VERSION ""

NS_ :

BS_:

BU_: Motor_VA_info Motor_Controller BMS
VAL_TABLE_ Charger_control 1 "Stop Charging" 0 "Start Charging" ;
VAL_TABLE_ Battery_Failure_level 3 "Level 3 Alarm" 2 "Level 2 Power reduced to 50%" 1 "Level 1 stop" 0 "No failure" ;
VAL_TABLE_ ChargeMOS_Status 1 "ChargeMOS On" 0 "ChargeMOS Off" ;
VAL_TABLE_ DisMOS_Status 1 "DisMOS On" 0 "DisMOS off" ;
VAL_TABLE_ Ready_State 1 "Ready" 0 "Not Ready" ;
VAL_TABLE_ Battery_Low_SOC 1 "Low SOC" 0 "Normal SOC" ;
VAL_TABLE_ Battery_Charging 1 "Charging" 0 "Not charging" ;
VAL_TABLE_ Charge_wire_status 1 "Charge Wire connected" 0 "Charge Wire not connected" ;

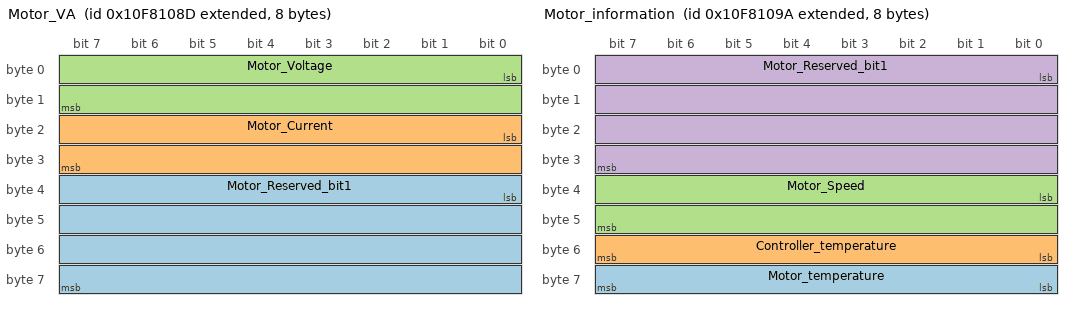
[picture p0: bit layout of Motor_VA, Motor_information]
BO_ 2432176269 Motor_VA: 8 Motor_VA_info
 SG_ Motor_Reserved_bit1 : 32|32@1- (1,0) [0|0] ""  Motor_VA_info
 SG_ Motor_Current : 16|16@1- (0.1,0) [0|0] ""  Motor_VA_info
 SG_ Motor_Voltage : 0|16@1+ (0.1,0) [0|6553.5] "V"  Motor_VA_info

BO_ 2432176282 Motor_information: 8 Motor_Controller
 SG_ Motor_temperature : 56|8@1+ (1,-40) [-40|215] "degC"  Motor_Controller
 SG_ Controller_temperature : 48|8@1+ (1,-40) [-40|215] "degC"  Motor_Controller
 SG_ Motor_Speed : 32|16@1+ (1,0) [0|65535] "RPM"  Motor_Controller
 SG_ Motor_Reserved_bit1 : 0|32@1- (1,0) [0|0] ""  Motor_Controller

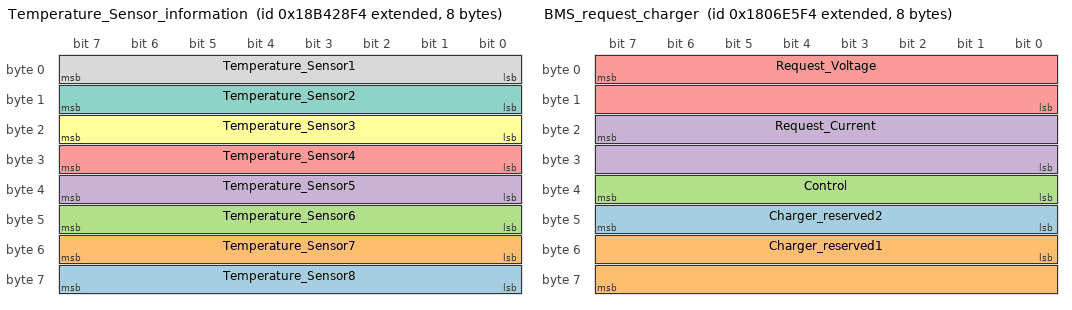
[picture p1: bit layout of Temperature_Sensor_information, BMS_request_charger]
BO_ 2561943796 Temperature_Sensor_information: 8 BMS
 SG_ Temperature_Sensor8 : 56|8@1+ (1,-40) [-40|215] "degC"  BMS
 SG_ Temperature_Sensor7 : 48|8@1+ (1,-40) [-40|215] "degC"  BMS
 SG_ Temperature_Sensor6 : 40|8@1+ (1,-40) [-40|215] "degC"  BMS
 SG_ Temperature_Sensor5 : 32|8@1+ (1,-40) [-40|215] "degC"  BMS
 SG_ Temperature_Sensor4 : 24|8@1+ (1,-40) [-40|215] "degC"  BMS
 SG_ Temperature_Sensor3 : 16|8@1+ (1,-40) [-40|215] "degC"  BMS
 SG_ Temperature_Sensor2 : 8|8@1+ (1,-40) [-40|215] "degC"  BMS
 SG_ Temperature_Sensor1 : 0|8@1+ (1,-40) [-40|215] "degC"  BMS

BO_ 2550588916 BMS_request_charger: 8 BMS
 SG_ Charger_reserved2 : 40|8@1- (1,0) [0|0] ""  BMS
 SG_ Charger_reserved1 : 48|16@1- (1,0) [0|0] ""  BMS
 SG_ Control : 32|8@1+ (1,0) [0|0] ""  BMS
 SG_ Request_Current : 23|16@0+ (0.1,0) [0|6553.5] "A"  BMS
 SG_ Request_Voltage : 7|16@0+ (0.1,0) [0|6553.5] "V"  BMS

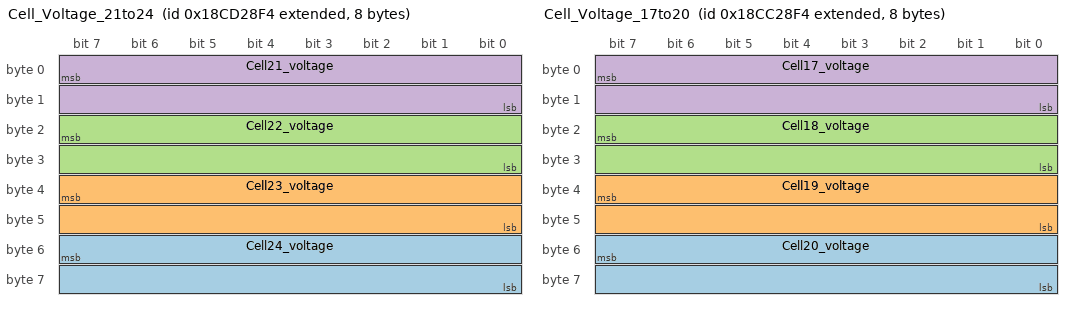
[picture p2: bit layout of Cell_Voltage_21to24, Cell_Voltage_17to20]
BO_ 2563582196 Cell_Voltage_21to24: 8 BMS
 SG_ Cell24_voltage : 55|16@0+ (0.001,0) [0|65.535] "V"  BMS
 SG_ Cell23_voltage : 39|16@0+ (0.001,0) [0|65.535] "V"  BMS
 SG_ Cell22_voltage : 23|16@0+ (0.001,0) [0|65.535] "V"  BMS
 SG_ Cell21_voltage : 7|16@0+ (0.001,0) [0|65.535] "V"  BMS

BO_ 2563516660 Cell_Voltage_17to20: 8 BMS
 SG_ Cell20_voltage : 55|16@0+ (0.001,0) [0|65.535] "V"  BMS
 SG_ Cell19_voltage : 39|16@0+ (0.001,0) [0|65.535] "V"  BMS
 SG_ Cell18_voltage : 23|16@0+ (0.001,0) [0|65.535] "V"  BMS
 SG_ Cell17_voltage : 7|16@0+ (0.001,0) [0|65.535] "V"  BMS

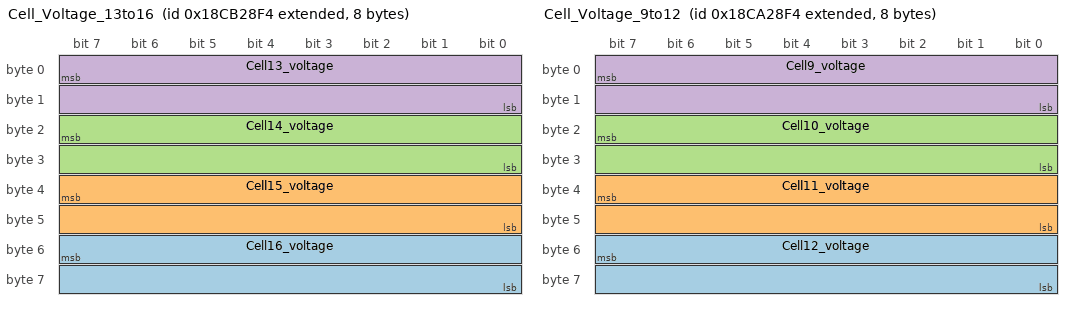
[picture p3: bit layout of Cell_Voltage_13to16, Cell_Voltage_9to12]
BO_ 2563451124 Cell_Voltage_13to16: 8 BMS
 SG_ Cell16_voltage : 55|16@0+ (0.001,0) [0|65.535] "V"  BMS
 SG_ Cell15_voltage : 39|16@0+ (0.001,0) [0|65.535] "V"  BMS
 SG_ Cell14_voltage : 23|16@0+ (0.001,0) [0|65.535] "V"  BMS
 SG_ Cell13_voltage : 7|16@0+ (0.001,0) [0|65.535] "V"  BMS

BO_ 2563385588 Cell_Voltage_9to12: 8 BMS
 SG_ Cell12_voltage : 55|16@0+ (0.001,0) [0|65.535] "V"  BMS
 SG_ Cell11_voltage : 39|16@0+ (0.001,0) [0|65.535] "V"  BMS
 SG_ Cell10_voltage : 23|16@0+ (0.001,0) [0|65.535] "V"  BMS
 SG_ Cell9_voltage : 7|16@0+ (0.001,0) [0|65.535] "V"  BMS

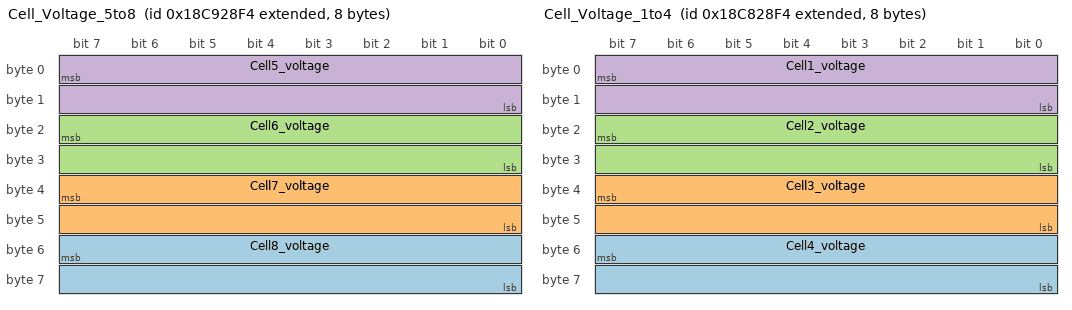
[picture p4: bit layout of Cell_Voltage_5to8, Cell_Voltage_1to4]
BO_ 2563320052 Cell_Voltage_5to8: 8 BMS
 SG_ Cell8_voltage : 55|16@0+ (0.001,0) [0|65.535] "V"  BMS
 SG_ Cell7_voltage : 39|16@0+ (0.001,0) [0|65.535] "V"  BMS
 SG_ Cell6_voltage : 23|16@0+ (0.001,0) [0|65.535] "V"  BMS
 SG_ Cell5_voltage : 7|16@0+ (0.001,0) [0|65.535] "V"  BMS

BO_ 2563254516 Cell_Voltage_1to4: 8 BMS
 SG_ Cell4_voltage : 55|16@0+ (0.001,0) [0|65.535] "V"  BMS
 SG_ Cell3_voltage : 39|16@0+ (0.001,0) [0|65.535] "V"  BMS
 SG_ Cell2_voltage : 23|16@0+ (0.001,0) [0|65.535] "V"  BMS
 SG_ Cell1_voltage : 7|16@0+ (0.001,0) [0|65.535] "V"  BMS

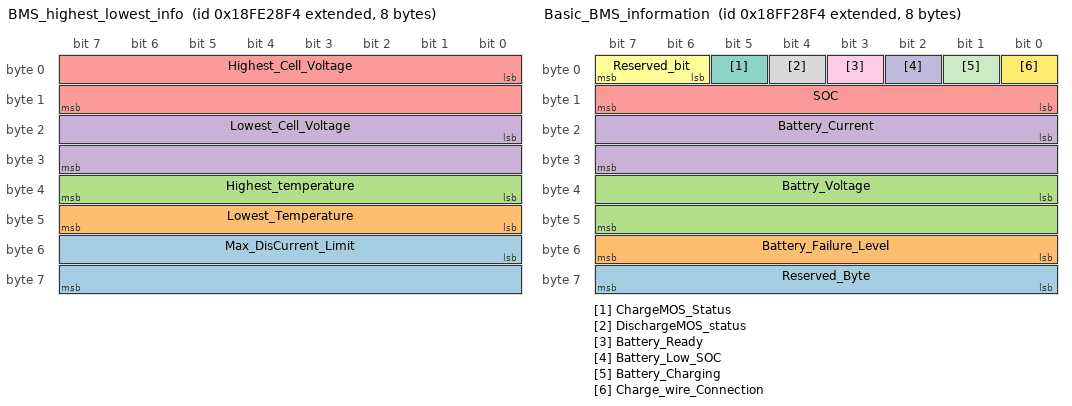
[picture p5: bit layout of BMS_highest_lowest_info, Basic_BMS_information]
BO_ 2566793460 BMS_highest_lowest_info: 8 BMS
 SG_ Max_DisCurrent_Limit : 48|16@1+ (0.1,0) [0|6553.5] "A"  BMS
 SG_ Lowest_Temperature : 40|8@1+ (1,-40) [-40|215] "degC"  BMS
 SG_ Highest_temperature : 32|8@1+ (1,-40) [-40|215] "degC"  BMS
 SG_ Lowest_Cell_Voltage : 16|16@1+ (0.001,0) [0|65.535] "V"  BMS
 SG_ Highest_Cell_Voltage : 0|16@1+ (0.001,0) [0|65.535] "V"  BMS

BO_ 2566858996 Basic_BMS_information: 8 BMS
 SG_ Reserved_Byte : 56|8@1- (1,0) [0|0] ""  BMS
 SG_ Battery_Failure_Level : 48|8@1+ (1,0) [0|0] ""  BMS
 SG_ Battry_Voltage : 32|16@1+ (0.1,0) [0|1000] "V"  BMS
 SG_ Battery_Current : 16|16@1+ (0.1,-500) [-500|500] "A"  BMS
 SG_ SOC : 8|8@1+ (1,0) [0|100] "%"  BMS
 SG_ Reserved_bit : 6|2@1- (1,0) [0|0] ""  BMS
 SG_ ChargeMOS_Status : 5|1@1+ (1,0) [0|1] ""  BMS
 SG_ DischargeMOS_status : 4|1@1+ (1,0) [0|1] ""  BMS
 SG_ Battery_Ready : 3|1@1+ (1,0) [0|1] ""  BMS
 SG_ Battery_Low_SOC : 2|1@1+ (1,0) [0|1] ""  BMS
 SG_ Battery_Charging : 1|1@1+ (1,0) [0|1] ""  BMS
 SG_ Charge_wire_Connection : 0|1@1+ (1,0) [0|1] ""  BMS

BA_DEF_ SG_  "GenSigStartValue" INT 0 2147483647;
BA_DEF_ SG_  "GenSigSendType" ENUM  "Cyclic","OnWrite","OnWriteWithRepetition","OnChange","OnChangeWithRepetition","IfActive","IfActiveWithRepetition","NoSigSendType";
BA_DEF_ SG_  "GenSigILSupport" ENUM  "No","Yes";
BA_DEF_ SG_  "SigType" ENUM  "Default","Range","RangeSigned","ASCII","Discrete","Control","ReferencePGN","DTC","StringDelimiter","StringLength","StringLengthControl","MessageCounter","MessageChecksum";
BA_DEF_ BO_  "VFrameFormat" ENUM  "StandardCAN","ExtendedCAN","reserved","J1939PG","reserved","reserved","reserved","reserved","reserved","reserved","reserved","reserved","reserved","reserved","StandardCAN_FD","ExtendedCAN_FD";
BA_DEF_ BO_  "GenMsgRequestable" INT 0 1;
BA_DEF_ BO_  "GenMsgSendType" ENUM  "cyclic","NotUsed","NotUsed","NotUsed","NotUsed","NotUsed","NotUsed","IfActive","noMsgSendType";
BA_DEF_ BO_  "GenMsgILSupport" ENUM  "No","Yes";
BA_DEF_ BO_  "J1939CPgTOS" INT 0 7;
BA_DEF_ BO_  "J1939CPgSendTimeout" INT -1 3600000;
BA_DEF_ BO_  "J1939PgAppearanceOnBus" ENUM  "Default","CAN_Extended","CANFD_Extended";
BA_DEF_ BU_  "NmStationAddress" INT 0 255;
BA_DEF_ BU_  "J1939MultiPgBroadcastType" ENUM  "FBFF","FEFF";
BA_DEF_ BU_  "J1939MultiPgSizeThreshold" INT 0 64;
BA_DEF_ BU_  "J1939MultiPgSendTimeout" INT 0 3600000;
BA_DEF_  "ProtocolType" STRING ;
BA_DEF_  "BusType" STRING ;
BA_DEF_  "DBName" STRING ;
BA_DEF_DEF_  "GenSigStartValue" 0;
BA_DEF_DEF_  "GenSigSendType" "NoSigSendType";
BA_DEF_DEF_  "GenSigILSupport" "Yes";
BA_DEF_DEF_  "SigType" "Default";
BA_DEF_DEF_  "VFrameFormat" "J1939PG";
BA_DEF_DEF_  "GenMsgRequestable" 1;
BA_DEF_DEF_  "GenMsgSendType" "noMsgSendType";
BA_DEF_DEF_  "GenMsgILSupport" "Yes";
BA_DEF_DEF_  "J1939CPgTOS" 2;
BA_DEF_DEF_  "J1939CPgSendTimeout" -1;
BA_DEF_DEF_  "J1939PgAppearanceOnBus" "Default";
BA_DEF_DEF_  "NmStationAddress" 254;
BA_DEF_DEF_  "J1939MultiPgBroadcastType" "FBFF";
BA_DEF_DEF_  "J1939MultiPgSizeThreshold" 56;
BA_DEF_DEF_  "J1939MultiPgSendTimeout" 2;
BA_DEF_DEF_  "ProtocolType" "J1939";
BA_DEF_DEF_  "BusType" "CAN";
BA_DEF_DEF_  "DBName" "";
BA_ "DBName" "Yatri_CAN";
BA_ "NmStationAddress" BU_ Motor_VA_info 141;
BA_ "NmStationAddress" BU_ Motor_Controller 154;
BA_ "NmStationAddress" BU_ BMS 244;
BA_ "VFrameFormat" BO_ 2432176269 1;
BA_ "VFrameFormat" BO_ 2432176282 1;
BA_ "VFrameFormat" BO_ 2561943796 1;
BA_ "VFrameFormat" BO_ 2550588916 1;
BA_ "VFrameFormat" BO_ 2563582196 1;
BA_ "VFrameFormat" BO_ 2563516660 1;
BA_ "VFrameFormat" BO_ 2563451124 1;
BA_ "VFrameFormat" BO_ 2563385588 1;
BA_ "VFrameFormat" BO_ 2563320052 1;
BA_ "VFrameFormat" BO_ 2563254516 1;
BA_ "VFrameFormat" BO_ 2566793460 1;
BA_ "VFrameFormat" BO_ 2566858996 1;
BA_ "GenSigStartValue" SG_ 2432176282 Motor_temperature 40;
BA_ "GenSigStartValue" SG_ 2432176282 Controller_temperature 40;
BA_ "GenSigStartValue" SG_ 2561943796 Temperature_Sensor8 40;
BA_ "GenSigStartValue" SG_ 2561943796 Temperature_Sensor7 40;
BA_ "GenSigStartValue" SG_ 2561943796 Temperature_Sensor6 40;
BA_ "GenSigStartValue" SG_ 2561943796 Temperature_Sensor5 40;
BA_ "GenSigStartValue" SG_ 2561943796 Temperature_Sensor4 40;
BA_ "GenSigStartValue" SG_ 2561943796 Temperature_Sensor3 40;
BA_ "GenSigStartValue" SG_ 2561943796 Temperature_Sensor2 40;
BA_ "GenSigStartValue" SG_ 2561943796 Temperature_Sensor1 40;
BA_ "GenSigStartValue" SG_ 2566793460 Lowest_Temperature 40;
BA_ "GenSigStartValue" SG_ 2566793460 Highest_temperature 40;
BA_ "GenSigStartValue" SG_ 2566858996 Battery_Current 5000;
VAL_ 2550588916 Control 1 "Stop Charging" 0 "Start Charging" ;
VAL_ 2566858996 Battery_Failure_Level 3 "Level 3 Alarm" 2 "Level 2 Power reduced to 50%" 1 "Level 1 stop" 0 "No failure" ;
VAL_ 2566858996 ChargeMOS_Status 1 "ChargeMOS On" 0 "ChargeMOS Off" ;
VAL_ 2566858996 DischargeMOS_status 1 "DisMOS On" 0 "DisMOS off" ;
VAL_ 2566858996 Battery_Ready 1 "Ready" 0 "Not Ready" ;
VAL_ 2566858996 Battery_Low_SOC 1 "Low SOC" 0 "Normal SOC" ;
VAL_ 2566858996 Battery_Charging 1 "Charging" 0 "Not charging" ;
VAL_ 2566858996 Charge_wire_Connection 1 "Charge Wire connected" 0 "Charge Wire not connected" ;
